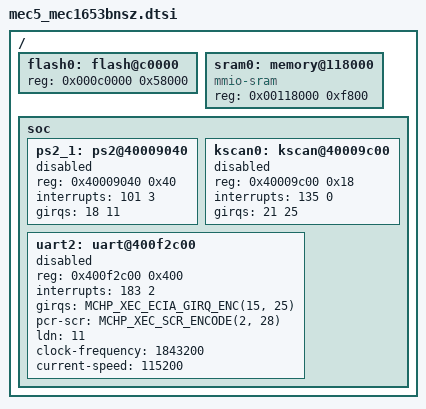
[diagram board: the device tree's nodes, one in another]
/*
 * Copyright (c) 2025 Microchip Technology Inc.
 *
 * SPDX-License-Identifier: Apache-2.0
 */

#include <arm/armv7-m.dtsi>

#include "mec5.dtsi"

/ {
	flash0: flash@c0000 {
		reg = <0x000c0000 0x58000>;
	};

	sram0: memory@118000 {
		compatible = "mmio-sram";
		reg = <0x00118000 0xf800>;
	};

	soc {
		#include "mec5/mec5_dma_chan20.dtsi"
		#include "mec5/mec5_eeprom_8kb.dtsi"
		#include "mec5/mec5_i3c.dtsi"

		ps2_1: ps2@40009040 {
			reg = <0x40009040 0x40>;
			interrupts = <101 3>;
			girqs = <18 11>;
			#address-cells = <1>;
			#size-cells = <0>;
			status = "disabled";
		};

		kscan0: kscan@40009c00 {
			reg = <0x40009c00 0x18>;
			interrupts = <135 0>;
			girqs = <21 25>;
			status = "disabled";
		};

		uart2: uart@400f2c00 {
			reg = <0x400f2c00 0x400>;
			interrupts = <183 2>;
			girqs = <MCHP_XEC_ECIA_GIRQ_ENC(15, 25)>;
			pcr-scr = <MCHP_XEC_SCR_ENCODE(2, 28)>;
			ldn = <11>;
			clock-frequency = <1843200>;
			current-speed = <115200>;
			status = "disabled";
		};
	};
};
